# ARMv8M-Extended register map
Registers are read-only, no defined reset value unless marked. A register's access mark holds for its fields unless they carry their own. Offsets are from the block's base; [hi:lo] are bit positions; {n}, {i} and the like mark numbered series.

## EWIC_IStat — External Wakeup Interrupt Controller Interrupt Status Access
Base 0xE001E400
0x00 EVENTSPR wo — Event Set Pending Register set pending events at wakeup that cannot be directly set in the Nested Vectored Interrupt Controller (NVIC) using the architecture programming model
  [2] EDBGREQ — Causes the processor to behave like an external debug request has occurred
    0=Ignored; 1=Processor to behave like an external debug request has occurred
  [1] NMI — Causes the processor to behave like a Non-maskable Interrupt (NMI) has occurred
    0=Ignored; 1=Processor to behave like a Non-maskable Interrupt (NMI) has occurred
  [1] EVENT — Causes the processor to behave like an RXEV event has occurred
    0=Ignored; 1=Processor to behave like an RXEV event has occurred
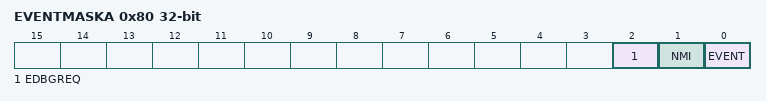
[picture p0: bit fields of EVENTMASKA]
0x80 EVENTMASKA — Wake-up Event Mask Register A provides the events on sleep entry which cause the processor to wake up, including information about internal events
  [2] EDBGREQ — Mask for external debug request
  [1] NMI — Mask for Non-Maskable Interrupt (NMI)
  [0] EVENT — Sensitive to RXEV when in WFE sleep
{0x84+4i} Wake-up Event Mask Register {i} (i=0..31) — Provides the events on sleep entry which cause the processor to wake up, including information about external events
  [31:0] IRQ — Masks for interrupts ((n-1)x32) to (nx32)-1.

## MPU — Memory Protection Unit
Base 0xE000ED90
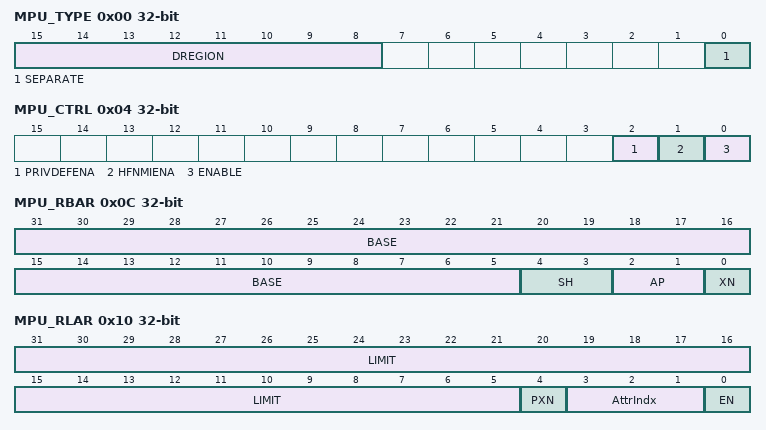
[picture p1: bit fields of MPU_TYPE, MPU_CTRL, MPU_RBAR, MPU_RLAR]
0x00 MPU_TYPE — MPU Type Register indicates whether the MPU is present, and if so, how many regions it supports
  [15:8] DREGION — Number of regions supported by the MPU
    0=0 regions if your device does not include the MPU; 4=4 regions if your device includes the MPU; 8=8 regions if your device includes the MPU; 12=12 regions if your device includes the MPU; 16=16 regions if your device includes the MPU
  [0] SEPARATE — Indicates support for unified or separate instructions and data address regions
    0=Unified
0x04 MPU_CTRL rw — MPU Control Register enables the MPU
  [2] PRIVDEFENA — Enables privileged software access to the default memory map
    0=Disables use of the default memory map. Any memory access to a location that is not covered by any enabled region causes a fault.; 1=Enables use of the default memory map as a background region for privileged software accesses
  [1] HFNMIENA — Enables the operation of MPU during HardFault and NMI handlers
    0=MPU is disabled during HardFault and NMI handlers, regardless of the value of the ENABLE bit; 1=The MPU is enabled during HardFault and NMI handlers
  [0] ENABLE — Enables the MPU
    0=MPU is disabled; 1=MPU is enabled
0x08 MPU_RNR rw — MPU Region Number Register selects the region currently accessed by MPU_RBAR and MPU_RLAR
  [7:0] REGION — Indicates the memory region accessed by MPU_RBAR and PMU_RLAR
0x0C MPU_RBAR rw — MPU Region Base Address Register defines the base address of the MPU region selected by the MPU_RNR
  [31:5] BASE — Contains bits[31:5] of the lower inclusive limit of the selected MPU memory region. This value is zero extended to provide the base address to be checked against.
  [4:3] SH — Defines the shareability domain of this region for Normal memory
    0=Non-shareable; 1=unpredictable; 2=Outer shareable; 3=Inner Shareable
  [2:1] AP — Access permissions
    0=Read/write by privileged code only; 1=Read/write by any privilege level; 2=Read-only by privileged code only; 3=Read-only by any privilege level
  [0] XN — Defines whether code can be executed from this region
    0=Execution only permitted if read permitted; 1=Execution not permitted
0x10 MPU_RLAR rw — MPU Region Limit Address Register defines the limit address of the MPU region selected by the MPU_RNR
  [31:5] LIMIT — Contains bits[31:5] of the upper inclusive limit of the selected MPU memory region. This value is postfixed with 0x1F to provide the limit address to be checked against.
  [4] PXN — Defines whether code can be executed from this privileged region
    0=Execution only permitted if read permitted; 1=Execution from a privileged mode is not permitted
  [3:1] AttrIndx — Associates a set of attributes in the MPU_MAIR0 and MPU_MAIR1 fields
  [0] EN — Region enable
    0=Region disabled; 1=Region enabled
{0x10+4i} MPU_RBAR_A{i} rw (i=1..3) — MPU Region Base Address Register Alias {i} provides indirect read and write access to the MPU base address register
{0x1C+4i} MPU_RLAR_A{i} rw (i=1..3) — MPU Region Limit Address Register Alias {i} provides indirect read and write access to the MPU limit address register
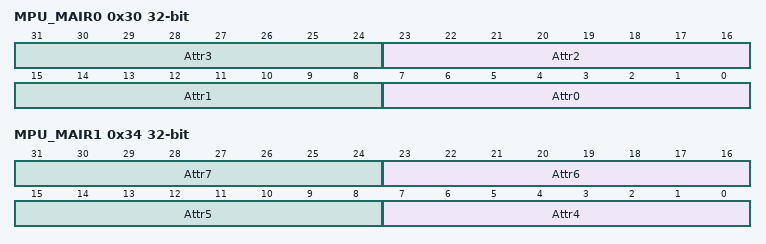
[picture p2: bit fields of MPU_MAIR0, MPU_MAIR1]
0x30 MPU_MAIR0 rw — MPU Memory Attribute Indirection Register 0 provides the memory attribute encodings corresponding to the AttrIndex values
  [8n+7:8n] Attr{n} (n=0..3) — Memory attribute encoding for MPU regions with an AttrIndex of {n}
0x34 MPU_MAIR1 rw — MPU Memory Attribute Indirection Register 1 provides the memory attribute encodings corresponding to the AttrIndex values
  [8n-25:8n-32] Attr{n} (n=4..7) — Memory attribute encoding for MPU regions with an AttrIndex of {n}
